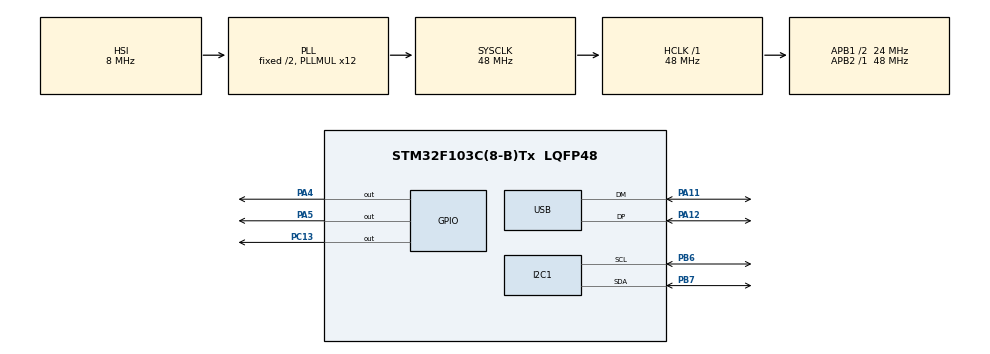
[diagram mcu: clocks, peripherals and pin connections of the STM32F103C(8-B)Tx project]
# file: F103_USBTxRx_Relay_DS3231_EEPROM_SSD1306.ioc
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I2C1.I2C_Mode=I2C_Fast
IWDG.Prescaler=IWDG_PRESCALER_32
Mcu.Family=STM32F1
Mcu.Name=STM32F103C(8-B)Tx
Mcu.Package=LQFP48
NVIC.PriorityGroup=NVIC_PRIORITYGROUP_4
NVIC.USB_LP_CAN1_RX0_IRQn=true\:0\:0\:false\:false\:true\:false\:true\:true
PA11.Mode=Device
PA11.Signal=USB_DM
PA12.Mode=Device
PA12.Signal=USB_DP
PA13.Mode=Serial_Wire
PA13.Signal=SYS_JTMS-SWDIO
PA14.Mode=Serial_Wire
PA14.Signal=SYS_JTCK-SWCLK
PA4.GPIO_PuPd=GPIO_PULLUP
PA4.GPIO_Speed=GPIO_SPEED_FREQ_HIGH
PA4.PinState=GPIO_PIN_SET
PA4.Signal=GPIO_Output
PA5.GPIO_PuPd=GPIO_PULLUP
PA5.GPIO_Speed=GPIO_SPEED_FREQ_HIGH
PA5.PinState=GPIO_PIN_SET
PA5.Signal=GPIO_Output
PB6.Mode=I2C
PB6.Signal=I2C1_SCL
PB7.Mode=I2C
PB7.Signal=I2C1_SDA
PC13-TAMPER-RTC.GPIO_PuPd=GPIO_PULLUP
PC13-TAMPER-RTC.GPIO_Speed=GPIO_SPEED_FREQ_HIGH
PC13-TAMPER-RTC.PinState=GPIO_PIN_SET
PC13-TAMPER-RTC.Signal=GPIO_Output
ProjectManager.HeapSize=0x1000
ProjectManager.StackSize=0x2000
ProjectManager.TargetToolchain=STM32CubeIDE
RCC.AHBFreq_Value=48000000
RCC.APB1CLKDivider=RCC_HCLK_DIV2
RCC.APB1Freq_Value=24000000
RCC.APB1TimFreq_Value=48000000
RCC.APB2Freq_Value=48000000
RCC.APB2TimFreq_Value=48000000
RCC.HCLKFreq_Value=48000000
RCC.PLLMUL=RCC_PLL_MUL12
RCC.PLLSourceVirtualString=RCC_PLLSOURCE_HSI_DIV2
RCC.SYSCLKFreq_VALUE=48000000
RCC.SYSCLKSource=RCC_SYSCLKSOURCE_PLLCLK
RCC.USBFreq_Value=48000000
USB_DEVICE.CLASS_NAME_FS=CDC
USB_DEVICE.VirtualMode=Cdc
USB_DEVICE.VirtualModeFS=Cdc_FS
VP_IWDG_VS_IWDG.Mode=IWDG_Activate
VP_USB_DEVICE_VS_USB_DEVICE_CDC_FS.Mode=CDC_FS
board=custom

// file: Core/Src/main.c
/* USER CODE BEGIN Header */
/**
  ******************************************************************************
  * @file           : main.c
  * @brief          : Main program body
  ******************************************************************************
  * @attention
  *
  * Copyright (c) 2025 STMicroelectronics.
  * All rights reserved.
  *
  * This software is licensed under terms that can be found in the LICENSE file
  * in the root directory of this software component.
  * If no LICENSE file comes with this software, it is provided AS-IS.
  *
  ******************************************************************************
  */
/* USER CODE END Header */
#include "main.h"
#include "usb_device.h"

/* USER CODE BEGIN Includes */
#include "Driver.h"
/* USER CODE END Includes */

I2C_HandleTypeDef hi2c1;

IWDG_HandleTypeDef hiwdg;

void SystemClock_Config(void);
static void MX_GPIO_Init(void);
static void MX_I2C1_Init(void);
static void MX_IWDG_Init(void);

int main(void)
{

  /* MCU Configuration--------------------------------------------------------*/

  /* Reset of all peripherals, Initializes the Flash interface and the Systick. */
  HAL_Init();

  /* Configure the system clock */
  SystemClock_Config();

  /* Initialize all configured peripherals */
  MX_GPIO_Init();
  MX_I2C1_Init();
  MX_IWDG_Init();
  MX_USB_DEVICE_Init();
  /* USER CODE BEGIN 2 */
  Proj_Init_Function();
  /* USER CODE END 2 */

  /* Infinite loop */
  while (1)
  {

    /* USER CODE BEGIN 3 */
	Proj_While_Function();
  }
  /* USER CODE END 3 */
}

void SystemClock_Config(void)
{
  RCC_OscInitTypeDef RCC_OscInitStruct = {0};
  RCC_ClkInitTypeDef RCC_ClkInitStruct = {0};
  RCC_PeriphCLKInitTypeDef PeriphClkInit = {0};

  /** Initializes the RCC Oscillators according to the specified parameters
  * in the RCC_OscInitTypeDef structure.
  */
  RCC_OscInitStruct.OscillatorType = RCC_OSCILLATORTYPE_HSI|RCC_OSCILLATORTYPE_LSI;
  RCC_OscInitStruct.HSIState = RCC_HSI_ON;
  RCC_OscInitStruct.HSICalibrationValue = RCC_HSICALIBRATION_DEFAULT;
  RCC_OscInitStruct.LSIState = RCC_LSI_ON;
  RCC_OscInitStruct.PLL.PLLState = RCC_PLL_ON;
  RCC_OscInitStruct.PLL.PLLSource = RCC_PLLSOURCE_HSI_DIV2;
  RCC_OscInitStruct.PLL.PLLMUL = RCC_PLL_MUL12;
  if (HAL_RCC_OscConfig(&RCC_OscInitStruct) != HAL_OK)
  {
    Error_Handler();
  }

  /** Initializes the CPU, AHB and APB buses clocks
  */
  RCC_ClkInitStruct.ClockType = RCC_CLOCKTYPE_HCLK|RCC_CLOCKTYPE_SYSCLK
                              |RCC_CLOCKTYPE_PCLK1|RCC_CLOCKTYPE_PCLK2;
  RCC_ClkInitStruct.SYSCLKSource = RCC_SYSCLKSOURCE_PLLCLK;
  RCC_ClkInitStruct.AHBCLKDivider = RCC_SYSCLK_DIV1;
  RCC_ClkInitStruct.APB1CLKDivider = RCC_HCLK_DIV2;
  RCC_ClkInitStruct.APB2CLKDivider = RCC_HCLK_DIV1;

  if (HAL_RCC_ClockConfig(&RCC_ClkInitStruct, FLASH_LATENCY_1) != HAL_OK)
  {
    Error_Handler();
  }
  PeriphClkInit.PeriphClockSelection = RCC_PERIPHCLK_USB;
  PeriphClkInit.UsbClockSelection = RCC_USBCLKSOURCE_PLL;
  if (HAL_RCCEx_PeriphCLKConfig(&PeriphClkInit) != HAL_OK)
  {
    Error_Handler();
  }
}

static void MX_I2C1_Init(void)
{

  hi2c1.Instance = I2C1;
  hi2c1.Init.ClockSpeed = 400000;
  hi2c1.Init.DutyCycle = I2C_DUTYCYCLE_2;
  hi2c1.Init.OwnAddress1 = 0;
  hi2c1.Init.AddressingMode = I2C_ADDRESSINGMODE_7BIT;
  hi2c1.Init.DualAddressMode = I2C_DUALADDRESS_DISABLE;
  hi2c1.Init.OwnAddress2 = 0;
  hi2c1.Init.GeneralCallMode = I2C_GENERALCALL_DISABLE;
  hi2c1.Init.NoStretchMode = I2C_NOSTRETCH_DISABLE;
  if (HAL_I2C_Init(&hi2c1) != HAL_OK)
  {
    Error_Handler();
  }

}

static void MX_IWDG_Init(void)
{

  hiwdg.Instance = IWDG;
  hiwdg.Init.Prescaler = IWDG_PRESCALER_32;
  hiwdg.Init.Reload = 4095;
  if (HAL_IWDG_Init(&hiwdg) != HAL_OK)
  {
    Error_Handler();
  }

}

static void MX_GPIO_Init(void)
{
  GPIO_InitTypeDef GPIO_InitStruct = {0};

  /* GPIO Ports Clock Enable */
  __HAL_RCC_GPIOC_CLK_ENABLE();
  __HAL_RCC_GPIOA_CLK_ENABLE();
  __HAL_RCC_GPIOB_CLK_ENABLE();

  /*Configure GPIO pin Output Level */
  HAL_GPIO_WritePin(GPIOC, GPIO_PIN_13, GPIO_PIN_SET);

  /*Configure GPIO pin Output Level */
  HAL_GPIO_WritePin(GPIOA, GPIO_PIN_4|GPIO_PIN_5, GPIO_PIN_SET);

  /*Configure GPIO pin : PC13 */
  GPIO_InitStruct.Pin = GPIO_PIN_13;
  GPIO_InitStruct.Mode = GPIO_MODE_OUTPUT_PP;
  GPIO_InitStruct.Pull = GPIO_PULLUP;
  GPIO_InitStruct.Speed = GPIO_SPEED_FREQ_HIGH;
  HAL_GPIO_Init(GPIOC, &GPIO_InitStruct);

  /*Configure GPIO pins : PA4 PA5 */
  GPIO_InitStruct.Pin = GPIO_PIN_4|GPIO_PIN_5;
  GPIO_InitStruct.Mode = GPIO_MODE_OUTPUT_PP;
  GPIO_InitStruct.Pull = GPIO_PULLUP;
  GPIO_InitStruct.Speed = GPIO_SPEED_FREQ_HIGH;
  HAL_GPIO_Init(GPIOA, &GPIO_InitStruct);

}

void Error_Handler(void)
{
  __disable_irq();
  while (1)
  {
  }
}
